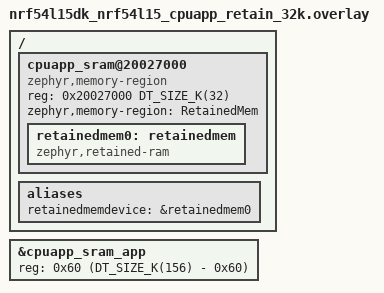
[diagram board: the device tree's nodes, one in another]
/ {
	cpuapp_sram@20027000 {
		compatible = "zephyr,memory-region", "mmio-sram";
		reg = <0x20027000 DT_SIZE_K(32)>;
		zephyr,memory-region = "RetainedMem";
		status = "okay";

		retainedmem0: retainedmem {
			compatible = "zephyr,retained-ram";
			status = "okay";
		};
	};

	aliases {
		retainedmemdevice = &retainedmem0;
	};
};

&cpuapp_sram_app {
	/* Shrink SRAM size to avoid overlap with retained memory region */
	reg = <0x60 (DT_SIZE_K(156) - 0x60)>;
};
